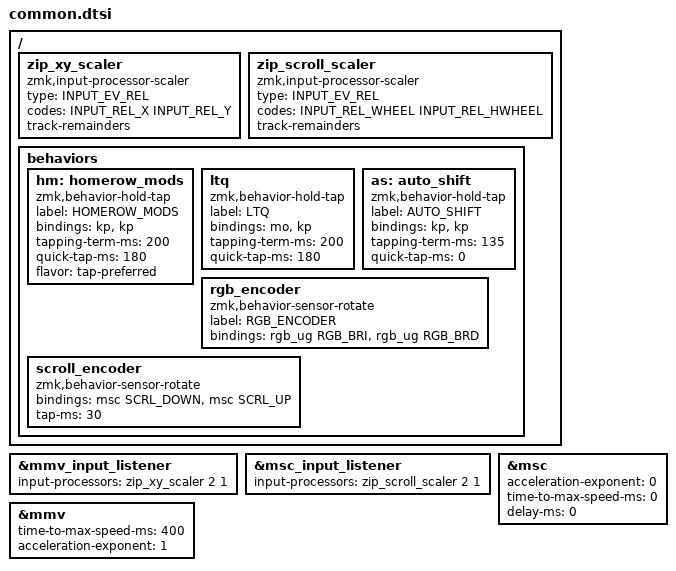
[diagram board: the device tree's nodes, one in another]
#include <input/processors.dtsi>
#include <behaviors.dtsi>
#include <dt-bindings/zmk/bt.h>
#include <dt-bindings/zmk/keys.h>
#include <dt-bindings/zmk/outputs.h>
#include <dt-bindings/zmk/pointing.h>
#include <dt-bindings/zmk/rgb.h>
#include <zephyr/dt-bindings/input/input-event-codes.h>

/* Global input processors and behaviors */
&mmv_input_listener {
    input-processors = <&zip_xy_scaler 2 1>;
};

&msc_input_listener {
    input-processors = <&zip_scroll_scaler 2 1>;
};

&msc {
    acceleration-exponent = <0>;
    time-to-max-speed-ms = <0>;
    delay-ms = <0>;
};

&mmv {
    time-to-max-speed-ms = <400>;
    acceleration-exponent = <1>;
};

/ {
    zip_xy_scaler: zip_xy_scaler {
        compatible = "zmk,input-processor-scaler";
        #input-processor-cells = <2>;
        type = <INPUT_EV_REL>;
        codes = <INPUT_REL_X INPUT_REL_Y>;
        track-remainders;
    };

    zip_scroll_scaler: zip_scroll_scaler {
        compatible = "zmk,input-processor-scaler";
        #input-processor-cells = <2>;
        type = <INPUT_EV_REL>;
        codes = <INPUT_REL_WHEEL INPUT_REL_HWHEEL>;
        track-remainders;
    };

    behaviors {
        hm: homerow_mods {
            compatible = "zmk,behavior-hold-tap";
            label = "HOMEROW_MODS";
            bindings = <&kp>, <&kp>;
            #binding-cells = <2>;
            tapping-term-ms = <200>;
            quick-tap-ms = <180>;
            flavor = "tap-preferred";
        };

        ltq: ltq {
            compatible = "zmk,behavior-hold-tap";
            label = "LTQ";
            bindings = <&mo>, <&kp>;
            #binding-cells = <2>;
            tapping-term-ms = <200>;
            quick-tap-ms = <180>;
        };

        as: auto_shift {
            compatible = "zmk,behavior-hold-tap";
            label = "AUTO_SHIFT";
            bindings = <&kp>, <&kp>;
            #binding-cells = <2>;
            tapping-term-ms = <135>;
            quick-tap-ms = <0>;
        };

        rgb_encoder: rgb_encoder {
            compatible = "zmk,behavior-sensor-rotate";
            label = "RGB_ENCODER";
            #sensor-binding-cells = <0>;
            bindings = <&rgb_ug RGB_BRI>, <&rgb_ug RGB_BRD>;
        };

        scroll_encoder: scroll_encoder {
            compatible = "zmk,behavior-sensor-rotate";
            #sensor-binding-cells = <0>;
            bindings = <&msc SCRL_DOWN>, <&msc SCRL_UP>;
            tap-ms = <30>;
        };
    };
};
